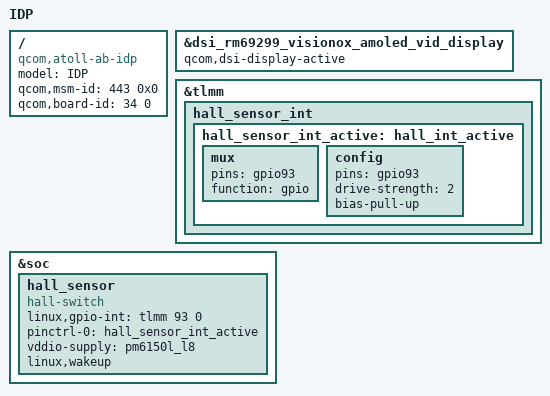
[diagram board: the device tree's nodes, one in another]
/* Copyright (c) 2019, The Linux Foundation. All rights reserved.
 *
 * This program is free software; you can redistribute it and/or modify
 * it under the terms of the GNU General Public License version 2 and
 * only version 2 as published by the Free Software Foundation.
 *
 * This program is distributed in the hope that it will be useful,
 * but WITHOUT ANY WARRANTY; without even the implied warranty of
 * MERCHANTABILITY or FITNESS FOR A PARTICULAR PURPOSE.  See the
 * GNU General Public License for more details.
 */

/dts-v1/;
/plugin/;

#include <dt-bindings/interrupt-controller/arm-gic.h>

#include "atoll-idp.dtsi"
/* Change wcd938x to wcd937x */
#include "atoll-wcd937x-idp-audio-overlay.dtsi"
#include "atoll-audio-idp-overlay.dtsi"

/ {
	model = "IDP";
	compatible = "qcom,atoll-ab-idp", "qcom,atoll-ab", "qcom,idp";
	qcom,msm-id = <443 0x0>;
	qcom,board-id = <34 0>;
};

&dsi_rm69299_visionox_amoled_vid_display {
	qcom,dsi-display-active;
};

&tlmm {
	hall_sensor_int {
		hall_sensor_int_active: hall_int_active {
			mux {
				pins = "gpio93";
				function = "gpio";
			};

			config {
				pins = "gpio93";
				drive-strength = <2>;
				bias-pull-up;
			};
		};
	};
};

&soc {
	hall_sensor {
		compatible = "hall-switch";
		linux,gpio-int = <&tlmm 93 0>;
		pinctrl-names = "default";
		pinctrl-0 = <&hall_sensor_int_active>;
		vddio-supply = <&pm6150l_l8>;
		linux,wakeup;

		status = "okay";
	};
};
